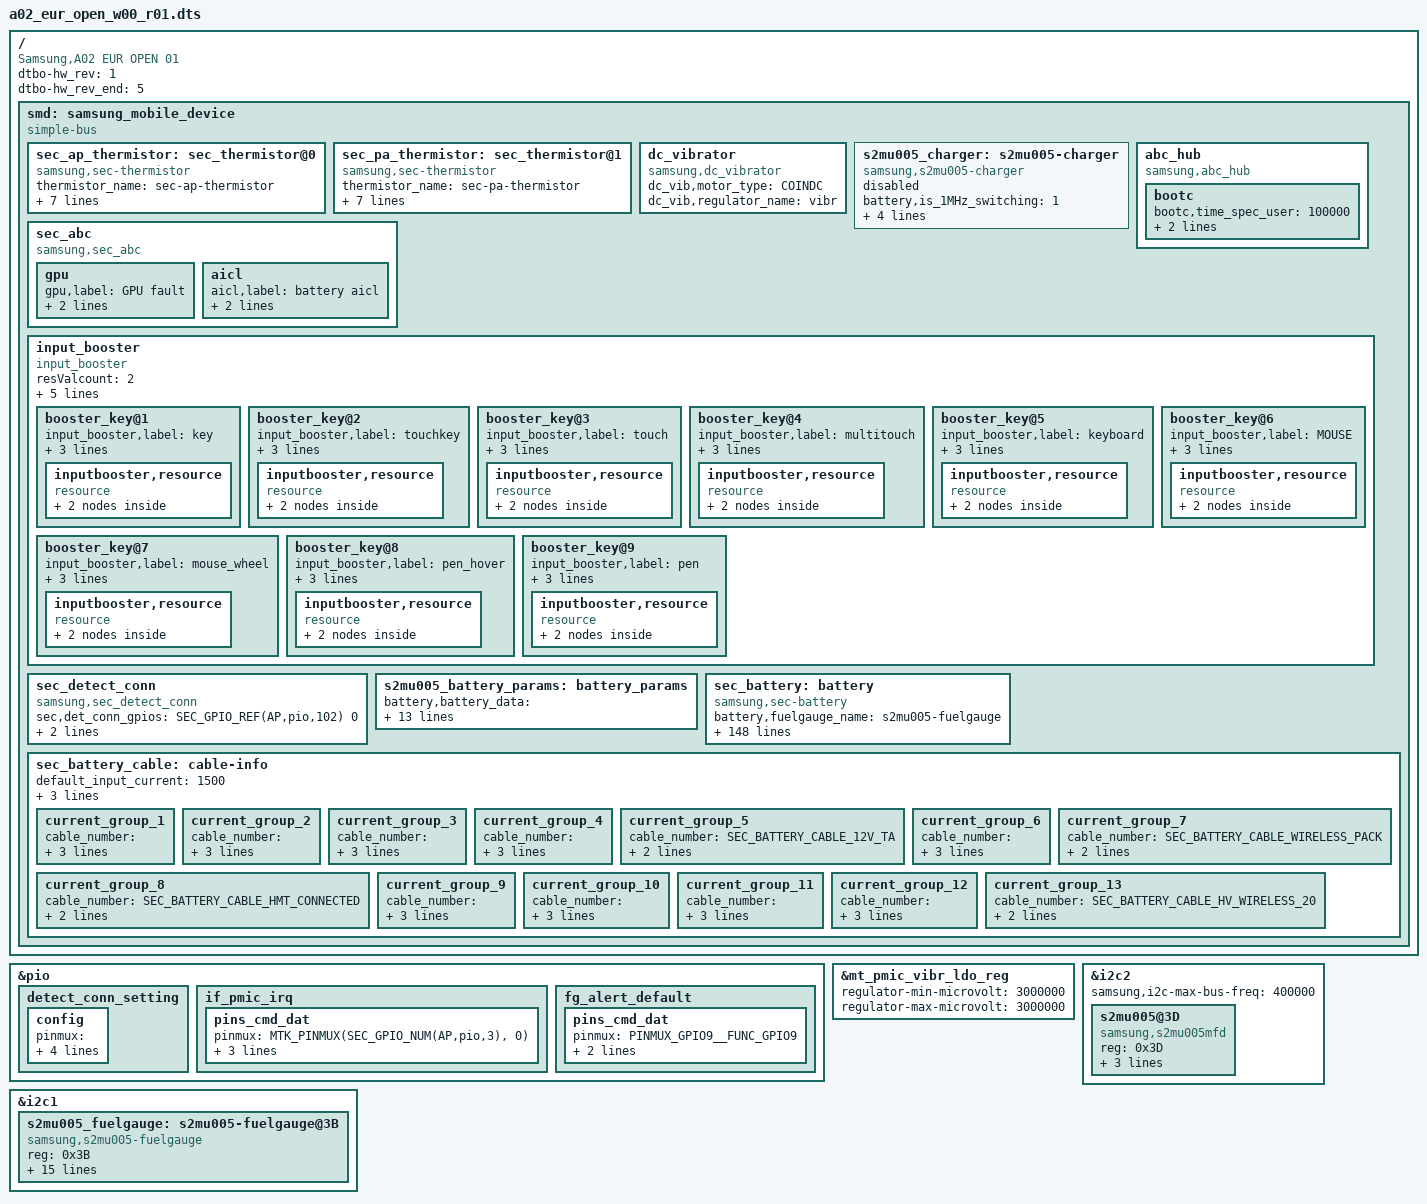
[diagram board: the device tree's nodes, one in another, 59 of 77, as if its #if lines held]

/*
 * Copyright (c) 2018 Samsung Electronics Co., Ltd.
 *              http://www.samsung.com
 *
 * This program is free software; you can redistribute it and/or modify
 * it under the terms of the GNU General Public License version 2 as
 * published by the Free Software Foundation.
*/

/dts-v1/;
/plugin/;
/ {
	fragment@smd {
		target-path = "/";
		__overlay__ {
			smd: samsung_mobile_device {
				compatible = "simple-bus";
			};
		};
	};
};

/* #include "../../../../../arm64/boot/dts/samsung/s2mu005_charger.dtsi" *//* From s2mu005_charger.py */

&smd {
	s2mu005_charger: s2mu005-charger {
		status = "disable";
		compatible = "samsung,s2mu005-charger";
		battery,is_1MHz_switching = <1>;
		battery,chg_gpio_en = <0>;
		battery,chg_polarity_en = <0>;
		battery,chg_gpio_status = <0>;
		battery,chg_polarity_status = <0>;
	};
};


/* #include "../../../../../arm64/boot/dts/samsung/sti_abc.dtsi" *//* From sti_abc.py */
#ifndef CONFIG_SEC_FACTORY

#if 0
&${gpio_sub_connect_conn_parent} {
	sub_detect_conn_setting: sub-detect-conn-setting {
		samsung,pins = SEC_GPIO(${gpio_sub_connect_conn});
		samsung,pin-function = <0xf>;
		samsung,pin-pud = <0>;
		samsung,pin-drv = <0>;
	};
};
#endif

#if 0
&${gpio_sub_connect_conn_parent2} {
	sub_detect_conn_setting2: sub-detect-conn-setting2 {
		samsung,pins = SEC_GPIO(${gpio_sub_connect_conn2});
		samsung,pin-function = <0xf>;
		samsung,pin-pud = <0>;
		samsung,pin-drv = <0>;
	};
};
#endif

#if 0
&${gpio_cam_connect_conn_parent} {
	cam_detect_conn_setting: cam-detect-conn-setting {
		samsung,pins = SEC_GPIO(${gpio_cam_connect_conn});
		samsung,pin-function = <0xf>;
		samsung,pin-pud = <0>;
		samsung,pin-drv = <0>;
	};
};
#endif

#if 0
&${det_gpio_num_parent} {
	detect_conn_setting: detect_conn_setting {
		config {
#if 0
			pins = SEC_GPIO(${det_gpio_num_0}),
			       SEC_GPIO(${det_gpio_num_1}),
			       SEC_GPIO(${det_gpio_num_2}),
			       SEC_GPIO(${det_gpio_num_3}),
			       SEC_GPIO(${det_gpio_num_4}),
#if 0
			       SEC_GPIO(${det_gpio_num_5}),
			       SEC_GPIO(${det_gpio_num_6}),
			       SEC_GPIO(${det_gpio_num_7});
#elif 0
			       SEC_GPIO(${det_gpio_num_5}),
			       SEC_GPIO(${det_gpio_num_6});
#else
			       SEC_GPIO(${det_gpio_num_5});
#endif
#elif 0
			pins = SEC_GPIO(${det_gpio_num_0}),
			       SEC_GPIO(${det_gpio_num_1}),
			       SEC_GPIO(${det_gpio_num_2}),
			       SEC_GPIO(${det_gpio_num_3}),
#if 0
			       SEC_GPIO(${det_gpio_num_4}),
			       SEC_GPIO(${det_gpio_num_6}),
			       SEC_GPIO(${det_gpio_num_7});
#elif 0
			       SEC_GPIO(${det_gpio_num_4}),
			       SEC_GPIO(${det_gpio_num_6});
#else
			       SEC_GPIO(${det_gpio_num_4});
#endif
#elif 0
			pins = SEC_GPIO(${det_gpio_num_0}),
			       SEC_GPIO(${det_gpio_num_1}),
			       SEC_GPIO(${det_gpio_num_2}),
#if 0
			       SEC_GPIO(${det_gpio_num_3}),
			       SEC_GPIO(${det_gpio_num_6}),
			       SEC_GPIO(${det_gpio_num_7});
#elif 0
			       SEC_GPIO(${det_gpio_num_3}),
			       SEC_GPIO(${det_gpio_num_6});
#else
			       SEC_GPIO(${det_gpio_num_3});
#endif
#elif 0
			pins = SEC_GPIO(${det_gpio_num_0}),
			       SEC_GPIO(${det_gpio_num_1}),
#if 0
			       SEC_GPIO(${det_gpio_num_2}),
			       SEC_GPIO(${det_gpio_num_6}),
			       SEC_GPIO(${det_gpio_num_7});
#elif 0
			       SEC_GPIO(${det_gpio_num_2}),
			       SEC_GPIO(${det_gpio_num_6});
#else
			       SEC_GPIO(${det_gpio_num_2});
#endif
#elif 0
			pins = SEC_GPIO(${det_gpio_num_0}),
#if 0
			       SEC_GPIO(${det_gpio_num_1}),
			       SEC_GPIO(${det_gpio_num_6}),
			       SEC_GPIO(${det_gpio_num_7});
#elif 0
			       SEC_GPIO(${det_gpio_num_1}),
			       SEC_GPIO(${det_gpio_num_6});
#else
			       SEC_GPIO(${det_gpio_num_1});
#endif
#elif 0
			pins =
#if 0
			       SEC_GPIO(${det_gpio_num_0}),
			       SEC_GPIO(${det_gpio_num_6}),
			       SEC_GPIO(${det_gpio_num_7});
#elif 0
			       SEC_GPIO(${det_gpio_num_0}),
			       SEC_GPIO(${det_gpio_num_6});
#else
			       SEC_GPIO(${det_gpio_num_0});
#endif
#elif 0
			pins = SEC_GPIO(${det_gpio_num_6}),
			       SEC_GPIO(${det_gpio_num_7});
#elif 0
			pins = SEC_GPIO(${det_gpio_num_6});
#endif
			drive-strength = <2>;
			bias-disable; /*NO PULL*/
			input-enable;
		};
	};
};
#endif /*use_dynamic_ap_gpio_detect*/

#if 0
&${det_pm_gpio_num_parent} {
	detect_conn_pm_setting: detect_conn_pm_setting {
#if 0 && 0
		pins = SEC_GPIO(${det_pm_gpio_num_0}),
		       SEC_GPIO(${det_pm_gpio_num_1});
#elif 0
		pins = SEC_GPIO(${det_pm_gpio_num_0});
#elif 0
		pins = SEC_GPIO(${det_pm_gpio_num_1});
#endif
		function = "normal";
		power-source = <0>;
		bias-disable; /*NO PULL*/
		input-enable;
	};
};
#endif /*use_dynamic_pm_gpio_detect*/

#endif /* not CONFIG_SEC_FACTORY */

&smd {
	sec_abc {
		compatible = "samsung,sec_abc";
		status = "okay";

		gpu {
			gpu,label="GPU fault";
#if 0
			gpu,threshold_count=<4>;
			gpu,threshold_time=<1200>;
#else
			gpu,threshold_count=<20>;
			gpu,threshold_time=<1200>;
#endif
		};
#if 0
		gpu_page {
			gpu_page,label="GPU page fault";
			gpu_page,threshold_count=<20>;
			gpu_page,threshold_time=<1200>;
		};
#endif
		aicl {
			aicl,label="battery aicl";
			aicl,threshold_count=<5>;
			aicl,threshold_time=<300>;
		};
#if 0
		motto {
			motto,label="motto info base";
			motto,info_bootcheck_base = <0x15860858>;
			motto,info_device_base = <0x1586085C>;
		};
#endif
	};
	abc_hub {
		compatible = "samsung,abc_hub";
		status = "okay";

#ifndef CONFIG_SEC_FACTORY
#if 0
#if 0 && 0
		pinctrl-names = "det_ap_connect","det_pm_connect";
		pinctrl-0 = <&detect_conn_setting>;
		pinctrl-1 = <&detect_conn_pm_setting>;
#elif 0
		pinctrl-names = "det_ap_connect";
		pinctrl-0 = <&detect_conn_setting>;
#elif 0
		pinctrl-names = "det_pm_connect";
		pinctrl-0 = <&detect_conn_pm_setting>;
#endif
/*not feature_abc_qcom_dt*/
#elif 0 && 0 && 0
		pinctrl-0 = <&sub_detect_conn_setting &sub_detect_conn_setting2 &cam_detect_conn_setting>;
#elif 0 && 0
		pinctrl-0 = <&sub_detect_conn_setting &cam_detect_conn_setting>;
#elif 0 && 0
		pinctrl-0 = <&sub_detect_conn_setting &sub_detect_conn_setting2>;
#elif 0
		pinctrl-0 = <&sub_detect_conn_setting>;
#elif 0
		pinctrl-0 = <&cam_detect_conn_setting>;
#endif
#endif /* not CONFIG_SEC_FACTORY */
		bootc {
			bootc,time_spec_user = <100000>; /* user binary user build */
			bootc,time_spec_eng = <150000>; /* user binary eng build */
			bootc,time_spec_fac = <100000>; /* factory binary */
		};

#ifndef CONFIG_SEC_FACTORY
#if 0
#if 0 || 0
		cond {
#if 0
			sec,det_conn_gpios = <
#if 0
					SEC_GPIO_REF(${det_gpio_num_0}) 0
#endif
#if 0
					SEC_GPIO_REF(${det_gpio_num_1}) 0
#endif
#if 0
					SEC_GPIO_REF(${det_gpio_num_2}) 0
#endif
#if 0
					SEC_GPIO_REF(${det_gpio_num_3}) 0
#endif
#if 0
					SEC_GPIO_REF(${det_gpio_num_4}) 0
#endif
#if 0
					SEC_GPIO_REF(${det_gpio_num_5}) 0
#endif
#if 0
					SEC_GPIO_REF(${det_gpio_num_6}) 0
#endif
#if 0
					SEC_GPIO_REF(${det_gpio_num_7}) 0
#endif
					>;
#if 0 || 0
			sec,det_conn_name =
#endif
#if 0 && 0
					"", "", "", "", "", "",
					"", "";
#elif 0
					"", "", "", "", "", "";
#elif 0
					"", "";
#endif
#endif /*use_dynamic_ap_gpio_detect*/

#if 0
			sec,det_pm_conn_gpios = <
#if 0
					SEC_GPIO_REF(${det_pm_gpio_num_0}) 0
#endif
#if 0
					SEC_GPIO_REF(${det_pm_gpio_num_1}) 0
#endif
					>;
#if 0 || 0
			sec,det_pm_conn_name =
#endif
#if 0 && 0
					"",
					"";
#elif 0
					"";
#elif 0
					"";
#endif
#endif /*use_dynamic_pm_gpio_detect */
		};
#endif /*use_dynamic_ap_gpio_detect || use_dynamic_pm_gpio_detect*/

/*not feature_abc_qcom_dt, feature_abc_lsi_dt*/
#elif 0 && 0 && 0
		cond {
			sec,det_conn_gpios = <SEC_GPIO_REF(${gpio_sub_connect_conn}) 0
						SEC_GPIO_REF(${gpio_sub_connect_conn2}) 0
						SEC_GPIO_REF(${gpio_cam_connect_conn}) 0>;
			sec,det_conn_name = "sub", "sub2", "cam";
			sec,det_conn_irq_type = <3>; /* BOTH EDGE */
		};
#elif 0 && 0
		cond {
			sec,det_conn_gpios = <SEC_GPIO_REF(${gpio_sub_connect_conn}) 0
						SEC_GPIO_REF(${gpio_cam_connect_conn}) 0>;
			sec,det_conn_name = "sub", "cam";
			sec,det_conn_irq_type = <3>; /* BOTH EDGE */
		};
#elif 0 && 0
		cond {
			sec,det_conn_gpios = <SEC_GPIO_REF(${gpio_sub_connect_conn}) 0
						SEC_GPIO_REF(${gpio_sub_connect_conn2}) 0>;
			sec,det_conn_name = "sub", "sub2";
			sec,det_conn_irq_type = <3>; /* BOTH EDGE */
		};
#elif 0
		cond {
			sec,det_conn_gpios = <SEC_GPIO_REF(${gpio_sub_connect_conn}) 0>;
			sec,det_conn_name = "sub";
			sec,det_conn_irq_type = <3>; /* BOTH EDGE */
		};
#elif 0
		cond {
			sec,det_conn_gpios = <SEC_GPIO_REF(${gpio_cam_connect_conn}) 0>;
			sec,det_conn_name = "cam";
			sec,det_conn_irq_type = <3>; /* BOTH EDGE */
		};
#endif
#endif /* not CONFIG_SEC_FACTORY */
	};
};

/* #include "../../../../../arm64/boot/dts/samsung/sec_pinctrl_wrapper.dtsi" *//* From sec_pinctrl_wrapper.py */
#define PIN_FUNC_INPUT		input-enable
#define PIN_FUNC_INPUT_WAKEUP	input-enable
#define PIN_FUNC_OUTPUT		output-enable
#define PIN_FUNC_OUTPUT_HIGH		output-high
#define PIN_FUNC_OUTPUT_LOW		output-low

#define PIN_PULL_NONE	bias-disable
#define PIN_PULL_DOWN	bias-pull-down
#define PIN_PULL_UP	bias-pull-up
#define PIN_PULL_OPEN	bias-high-impedance

/*
 * MTK_DRIVE_2mA  2
 * MTK_DRIVE_4mA  4
 * MTK_DRIVE_6mA  6
 * MTK_DRIVE_8mA  8
 * MTK_DRIVE_10mA 10
 * MTK_DRIVE_12mA 12
 * MTK_DRIVE_14mA 14
 * MTK_DRIVE_16mA 16
 */

#define PIN_DRV_LV1	2
#define PIN_DRV_LV2	4
#define PIN_DRV_LV3	6
#define PIN_DRV_LV4	8
#define PIN_DRV_LV5	10
#define PIN_DRV_LV6	12
#define PIN_DRV_LV7	14
#define PIN_DRV_LV8	16

#define PIN_EXPAND(pin) #pin

#define SEC_GPIO(src, type, num)	PIN_EXPAND(gpio##num)
#define SEC_GPIO_REF(src, type, num)	&type num
#define SEC_GPIO_NUM(src, type, num)	num
#define SEC_GPIO_TYPE(src, type, num)	&type

#define MTK_PINMUX(gpio, func) (MTK_PIN_NO(gpio) | func)

#define GPIO_CONFIG(_src, _type, _num, _func)		\
	pins_cmd_dat{					\
		pinmux = <MTK_PINMUX(SEC_GPIO_NUM(_src, _type, _num), 0)>;	\
		PIN_ ##_func;		\
	}

#define GPIO_CONFIG_PUD(_src, _type, _num, _func, _pull)	\
	pins_cmd_dat{					\
		pinmux = <MTK_PINMUX(SEC_GPIO_NUM(_src, _type, _num), 0)>;	\
		PIN_ ##_pull;				\
		PIN_ ##_func;		\
	}

#define GPIO_CONFIG_PUD_DRV(_src, _type, _num, _func, _pull, _drv)	\
	pins_cmd_dat{					\
		pinmux = <MTK_PINMUX(SEC_GPIO_NUM(_src, _type, _num), 0)>;	\
		PIN_ ##_pull;				\
		PIN_ ##_func;		\
		drive-strength = <PIN_ ##_drv>;	\
	}

#define SEC_ADC(type, num) <&type num>
#define SEC_ADC_OPT(type, num) ,<&type num>
#define SEC_ADC_NUM(type, num) <num>

/* #include "../../../../../arm64/boot/dts/samsung/input_booster.dtsi" *//* From input_booster.py */
/* Copyright (c) 2019, The Linux Foundation. All rights reserved.
 *
 * This program is free software; you can redistribute it and/or modify
 * it under the terms of the GNU General Public License version 2 and
 * only version 2 as published by the Free Software Foundation.
 *
 * This program is distributed in the hope that it will be useful,
 * but WITHOUT ANY WARRANTY; without even the implied warranty of
 * MERCHANTABILITY or FITNESS FOR A PARTICULAR PURPOSE.  See the
 * GNU General Public License for more details.
 */

&smd {
	input_booster {
		status = "okay";
		compatible = "input_booster";
		resValcount = "2";
		max_resource_count = "2";
		max_cluster_count = "3";
		#address-cells = <1>;
		#size-cells = <0>;

		/* Each Cpu Cluster Start Cpu */
		cpu_cluster_policy = "0";

		/* < CPU, DDR > */
		ib_release_values = "-1,-1";

		/* Select Allowed Resource Index Group */
		allowed_resources = "0,1";

		booster_key@1 {
			input_booster,label = "key";
			input_booster,type = <0>;	/* BOOSTER_DEVICE_KEY */

			/* Time table */
			input_booster,head_time = <200>;
			input_booster,tail_time = <0>;

			/* Resource Table Sequentially identified with index
			 * CPU's ID & Index : 0
			 * DDR's ID & Index : 1
			*/

			/* Input Booster Resource Frequency */
			inputbooster,resource {
				compatible = "resource";
				resource@1 {
					resource,label = "CPU";
					resource,value = <1274000 0>;
				};

				resource@2 {
					resource,label = "DDR";
					resource,value = <999 999>;
				};
			};
		};

		booster_key@2 {
			input_booster,label = "touchkey";
			input_booster,type = <1>;	/* BOOSTER_DEVICE_TOUCHKEY */

			/* Time table */
			input_booster,head_time = <1>;
			input_booster,tail_time = <300>;

			/* Input Booster Resource Frequency */
			inputbooster,resource {
				compatible = "resource";
				resource@1 {
					resource,label = "CPU";
					resource,value = <0 1053000>;
				};

				resource@2 {
					resource,label = "DDR";
					resource,value = <999 999>;
				};
			};
		};

		booster_key@3 {
			input_booster,label = "touch";
			input_booster,type = <2>;	/* BOOSTER_DEVICE_TOUCH */

			/* Time table */
			input_booster,head_time = <130>;
			input_booster,tail_time = <500>;

			/* Input Booster Resource Frequency */
			inputbooster,resource {
				compatible = "resource";
				resource@1 {
					resource,label = "CPU";
					resource,value = <1378000 1274000>;
				};

				resource@2 {
					resource,label = "DDR";
					resource,value = <999 999>;
				};
			};
		};

		booster_key@4 {
			input_booster,label = "multitouch";
			input_booster,type = <3>;	/* BOOSTER_DEVICE_MULTITOUCH */

			/* Time table */
			input_booster,head_time = <1000>;
			input_booster,tail_time = <500>;

			/* Input Booster Resource Frequency */
			inputbooster,resource {
				compatible = "resource";
				resource@1 {
					resource,label = "CPU";
					resource,value = <1378000 1274000>;
				};

				resource@2 {
					resource,label = "DDR";
					resource,value = <999 999>;
				};
			};
		};

		booster_key@5 {
			input_booster,label = "keyboard";
			input_booster,type = <4>;	/* BOOSTER_DEVICE_KEYBOARD */

			/* Time table */
			input_booster,head_time = <130>;
			input_booster,tail_time = <130>;

			/* Input Booster Resource Frequency */
			inputbooster,resource {
				compatible = "resource";
				resource@1 {
					resource,label = "CPU";
					resource,value = <1053000 1053000>;
				};

				resource@2 {
					resource,label = "DDR";
					resource,value = <999 999>;
				};
			};
		};

		booster_key@6 {
			input_booster,label = "MOUSE";
			input_booster,type = <5>;	/* BOOSTER_DEVICE_MOUSE */

			/* Time table */
			input_booster,head_time = <200>;
			input_booster,tail_time = <300>;

			/* Input Booster Resource Frequency */
			inputbooster,resource {
				compatible = "resource";
				resource@1 {
					resource,label = "CPU";
					resource,value = <1274000 1053000>;
				};

				resource@2 {
					resource,label = "DDR";
					resource,value = <999 999>;
				};
			};
		};

		booster_key@7 {
			input_booster,label = "mouse_wheel";
			input_booster,type = <6>;	/* BOOSTER_DEVICE_MOUSE */

			/* Time table */
			input_booster,head_time = <200>;
			input_booster,tail_time = <0>;

			/* Input Booster Resource Frequency */
			inputbooster,resource {
				compatible = "resource";
				resource@1 {
					resource,label = "CPU";
					resource,value = <1274000 0>;
				};

				resource@2 {
					resource,label = "DDR";
					resource,value = <999 999>;
				};
			};
		};

		booster_key@8 {
			input_booster,label = "pen_hover";
			input_booster,type = <7>;	/* BOOSTER_DEVICE_MOUSE */

			/* Time table */
			input_booster,head_time = <200>;
			input_booster,tail_time = <300>;

			/* Input Booster Resource Frequency */
			inputbooster,resource {
				compatible = "resource";
				resource@1 {
					resource,label = "CPU";
					resource,value = <1274000 1053000>;
				};

				resource@2 {
					resource,label = "DDR";
					resource,value = <999 999>;
				};
			};
		};

		booster_key@9 {
			input_booster,label = "pen";
			input_booster,type = <8>;	/* BOOSTER_DEVICE_MOUSE */

			/* Time table */
			input_booster,head_time = <200>;
			input_booster,tail_time = <600>;

			/* Input Booster Resource Frequency */
			inputbooster,resource {
				compatible = "resource";
				resource@1 {
					resource,label = "CPU";
					resource,value = <1274000 1053000>;
				};

				resource@2 {
					resource,label = "DDR";
					resource,value = <999 999>;
				};
			};
		};
		/* If you need to add new key type, add it this position */
	};
};

/* #include "../ap_mtk_mt6739.dtsi" */               /* From ap_mtk_mt6739.py */

#include <dt-bindings/clock/mt6739-clk.h>


/* /home/dpi/qb5_8814/workspace/P4_1716/android/kernel/kmodule/ap/mtk/mt6739/ap_mtk_mt6739.a02.01.dtsi */

#include "../../k39tv1_bsp_titan_hamster.dts"
#include "../../k39tv1_bsp_titan_hamster/gpio01.dtsi"



/* #include "../../../../../arm64/boot/dts/samsung/gpio_sec_detect_conn.dtsi" *//* From gpio_sec_detect_conn.py */
#ifdef CONFIG_SEC_FACTORY
#if 1
&pio {
	detect_conn_setting: detect_conn_setting {
		config {
#if 0
			pinmux = <MTK_PINMUX(SEC_GPIO_NUM(AP,pio,102), 0)>,
			       <MTK_PINMUX(SEC_GPIO_NUM(${det_gpio_num_1}), 0)>,
			       <MTK_PINMUX(SEC_GPIO_NUM(${det_gpio_num_2}), 0)>,
			       <MTK_PINMUX(SEC_GPIO_NUM(${det_gpio_num_3}), 0)>,
			       <MTK_PINMUX(SEC_GPIO_NUM(${det_gpio_num_4}), 0)>,
#if 0
			       <MTK_PINMUX(SEC_GPIO_NUM(${det_gpio_num_5}), 0)>,
			       <MTK_PINMUX(SEC_GPIO_NUM(${det_gpio_num_6}), 0)>,
			       <MTK_PINMUX(SEC_GPIO_NUM(${det_gpio_num_7}), 0)>;
#elif 0
			       <MTK_PINMUX(SEC_GPIO_NUM(${det_gpio_num_5}), 0)>,
			       <MTK_PINMUX(SEC_GPIO_NUM(${det_gpio_num_6}), 0)>;
#else
			       <MTK_PINMUX(SEC_GPIO_NUM(${det_gpio_num_5}), 0)>;
#endif
#elif 0
			pinmux = <MTK_PINMUX(SEC_GPIO_NUM(AP,pio,102), 0)>,
			       <MTK_PINMUX(SEC_GPIO_NUM(${det_gpio_num_1}), 0)>,
			       <MTK_PINMUX(SEC_GPIO_NUM(${det_gpio_num_2}), 0)>,
			       <MTK_PINMUX(SEC_GPIO_NUM(${det_gpio_num_3}), 0)>,
#if 0
			       <MTK_PINMUX(SEC_GPIO_NUM(${det_gpio_num_4}), 0)>,
			       <MTK_PINMUX(SEC_GPIO_NUM(${det_gpio_num_6}), 0)>,
			       <MTK_PINMUX(SEC_GPIO_NUM(${det_gpio_num_7}), 0)>;
#elif 0
			       <MTK_PINMUX(SEC_GPIO_NUM(${det_gpio_num_4}), 0)>,
			       <MTK_PINMUX(SEC_GPIO_NUM(${det_gpio_num_6}), 0)>;
#else
			       <MTK_PINMUX(SEC_GPIO_NUM(${det_gpio_num_4}), 0)>;
#endif
#elif 0
			pinmux = <MTK_PINMUX(SEC_GPIO_NUM(AP,pio,102), 0)>,
			       <MTK_PINMUX(SEC_GPIO_NUM(${det_gpio_num_1}), 0)>,
			       <MTK_PINMUX(SEC_GPIO_NUM(${det_gpio_num_2}), 0)>,
#if 0
			       <MTK_PINMUX(SEC_GPIO_NUM(${det_gpio_num_3}), 0)>,
			       <MTK_PINMUX(SEC_GPIO_NUM(${det_gpio_num_6}), 0)>,
			       <MTK_PINMUX(SEC_GPIO_NUM(${det_gpio_num_7}), 0)>;
#elif 0
			       <MTK_PINMUX(SEC_GPIO_NUM(${det_gpio_num_3}), 0)>,
			       <MTK_PINMUX(SEC_GPIO_NUM(${det_gpio_num_6}), 0)>;
#else
			       <MTK_PINMUX(SEC_GPIO_NUM(${det_gpio_num_3}), 0)>;
#endif
#elif 0
			pinmux = <MTK_PINMUX(SEC_GPIO_NUM(AP,pio,102), 0)>,
			       <MTK_PINMUX(SEC_GPIO_NUM(${det_gpio_num_1}), 0)>,
#if 0
			       <MTK_PINMUX(SEC_GPIO_NUM(${det_gpio_num_2}), 0)>,
			       <MTK_PINMUX(SEC_GPIO_NUM(${det_gpio_num_6}), 0)>,
			       <MTK_PINMUX(SEC_GPIO_NUM(${det_gpio_num_7}), 0)>;
#elif 0
			       <MTK_PINMUX(SEC_GPIO_NUM(${det_gpio_num_2}), 0)>,
			       <MTK_PINMUX(SEC_GPIO_NUM(${det_gpio_num_6}), 0)>;
#else
			       <MTK_PINMUX(SEC_GPIO_NUM(${det_gpio_num_2}), 0)>;
#endif
#elif 0
			pinmux = <MTK_PINMUX(SEC_GPIO_NUM(AP,pio,102), 0)>,
#if 0
			       <MTK_PINMUX(SEC_GPIO_NUM(${det_gpio_num_1}), 0)>,
			       <MTK_PINMUX(SEC_GPIO_NUM(${det_gpio_num_6}), 0)>,
			       <MTK_PINMUX(SEC_GPIO_NUM(${det_gpio_num_7}), 0)>;
#elif 0
			       <MTK_PINMUX(SEC_GPIO_NUM(${det_gpio_num_1}), 0)>,
			       <MTK_PINMUX(SEC_GPIO_NUM(${det_gpio_num_6}), 0)>;
#else
			       <MTK_PINMUX(SEC_GPIO_NUM(${det_gpio_num_1}), 0)>;
#endif
#elif 1
			pinmux =
#if 0
			       <MTK_PINMUX(SEC_GPIO_NUM(AP,pio,102), 0)>,
			       <MTK_PINMUX(SEC_GPIO_NUM(${det_gpio_num_6}), 0)>,
			       <MTK_PINMUX(SEC_GPIO_NUM(${det_gpio_num_7}), 0)>;
#elif 0
			       <MTK_PINMUX(SEC_GPIO_NUM(AP,pio,102), 0)>,
			       <MTK_PINMUX(SEC_GPIO_NUM(${det_gpio_num_6}), 0)>;
#else
			       <MTK_PINMUX(SEC_GPIO_NUM(AP,pio,102), 0)>;
#endif
#elif 0
			pinmux = <MTK_PINMUX(SEC_GPIO_NUM(${det_gpio_num_6}), 0)>,
			       <MTK_PINMUX(SEC_GPIO_NUM(${det_gpio_num_7}), 0)>;
#elif 0
			pinmux = <MTK_PINMUX(SEC_GPIO_NUM(${det_gpio_num_6}), 0)>;
#endif
			drive-strength = <2>;
			bias-disable; /*NO PULL*/
			input-enable;
		};
	};
};
#endif /*use_dynamic_ap_gpio_detect*/

#if 0
&${det_pm_gpio_num_parent} {
	detect_conn_pm_setting: detect_conn_pm_setting {
#if 0 && 0
		pinmux = <MTK_PINMUX(SEC_GPIO_NUM(${det_pm_gpio_num_0}), 0)>,
		       <MTK_PINMUX(SEC_GPIO_NUM(${det_pm_gpio_num_1}), 0)>;
#elif 0
		pinmux = <MTK_PINMUX(SEC_GPIO_NUM(${det_pm_gpio_num_0}), 0)>;
#elif 0
		pinmux = <MTK_PINMUX(SEC_GPIO_NUM(${det_pm_gpio_num_1}), 0)>;
#endif
		function = "normal";
		power-source = <0>;
		bias-disable; /*NO PULL*/
		input-enable;
	};
};
#endif /*use_dynamic_pm_gpio_detect*/

&smd {
	sec_detect_conn {
		compatible = "samsung,sec_detect_conn";
		status = "okay";

#if 1
		sec,det_conn_gpios = <
#if 1
					SEC_GPIO_REF(AP,pio,102) 0
#endif
#if 0
					SEC_GPIO_REF(${det_gpio_num_1}) 0
#endif
#if 0
					SEC_GPIO_REF(${det_gpio_num_2}) 0
#endif
#if 0
					SEC_GPIO_REF(${det_gpio_num_3}) 0
#endif
#if 0
					SEC_GPIO_REF(${det_gpio_num_4}) 0
#endif
#if 0
					SEC_GPIO_REF(${det_gpio_num_5}) 0
#endif
#if 0
					SEC_GPIO_REF(${det_gpio_num_6}) 0
#endif
#if 0
					SEC_GPIO_REF(${det_gpio_num_7}) 0
#endif
					>;
#if 1 || 0
		sec,det_conn_name =
#endif
#if 1 && 0
					"SUB_CONNECT", "", "", "", "", "",
					"", "";
#elif 1
					"SUB_CONNECT", "", "", "", "", "";
#elif 0
					"", "";
#endif
#endif /*use_dynamic_ap_gpio_detect*/

#if 0
		sec,det_pm_conn_gpios = <
#if 0
					SEC_GPIO_REF(${det_pm_gpio_num_0}) 0
#endif
#if 0
					SEC_GPIO_REF(${det_pm_gpio_num_1}) 0
#endif
					>;
#if 0 || 0
		sec,det_pm_conn_name =
#endif
#if 0 && 0
					"",
					"";
#elif 0
					"";
#elif 0
					"";
#endif
#endif /*use_dynamic_pm_gpio_detect*/

#if 1 && 0
		pinctrl-names = "det_ap_connect","det_pm_connect";
		pinctrl-0 = <&detect_conn_setting>;
		pinctrl-1 = <&detect_conn_pm_setting>;
#elif 1
		pinctrl-names = "det_ap_connect";
		pinctrl-0 = <&detect_conn_setting>;
#elif 0
		pinctrl-names = "det_pm_connect";
		pinctrl-0 = <&detect_conn_pm_setting>;
#endif
	};
};
#endif /* CONFIG_SEC_FACTORY */


/* #include "../../../../../arm64/boot/dts/samsung/pmic_MT6357.dtsi" *//* From pmic_MT6357.py */
#if 0 && 0
&mt_pmic_vfe28_ldo_reg {
    regulator-min-microvolt = <0>;
    regulator-max-microvolt = <0>;
     
     
};
#endif

#if 0 && 0
&mt_pmic_vxo22_ldo_reg {
    regulator-min-microvolt = <0>;
    regulator-max-microvolt = <0>;
     
     
};
#endif

#if 0 && 0
&mt_pmic_vrf18_ldo_reg {
    regulator-min-microvolt = <0>;
    regulator-max-microvolt = <0>;
     
     
};
#endif

#if 0 && 0
&mt_pmic_vrf12_ldo_reg {
    regulator-min-microvolt = <0>;
    regulator-max-microvolt = <0>;
     
     
};
#endif

#if 0 && 0
&mt_pmic_vefuse_ldo_reg {
    regulator-min-microvolt = <0>;
    regulator-max-microvolt = <0>;
     
     
};
#endif

#if 0 && 0
&mt_pmic_vcn33_wifi_ldo_reg {
    regulator-min-microvolt = <0>;
    regulator-max-microvolt = <0>;
     
     
};
#endif

#if 0 && 0
&mt_pmic_vcn28_ldo_reg {
    regulator-min-microvolt = <0>;
    regulator-max-microvolt = <0>;
     
     
};
#endif

#if 0 && 0
&mt_pmic_vcn18_ldo_reg {
    regulator-min-microvolt = <0>;
    regulator-max-microvolt = <0>;
     
     
};
#endif

#if 0 && 0
&mt_pmic_vcama_ldo_reg {
    regulator-min-microvolt = <0>;
    regulator-max-microvolt = <0>;
     
     
};
#endif

#if 0 && 0
&mt_pmic_vcamd_ldo_reg {
    regulator-min-microvolt = <0>;
    regulator-max-microvolt = <0>;
     
     
};
#endif

#if 0 && 0
&mt_pmic_vcamio_ldo_reg {
    regulator-min-microvolt = <0>;
    regulator-max-microvolt = <0>;
     
     
};
#endif

#if 0 && 0
&mt_pmic_vldo28_ldo_reg {
    regulator-min-microvolt = <0>;
    regulator-max-microvolt = <0>;
     
     
};
#endif

#if 0 && 0
&mt_pmic_vsram_others_ldo_reg {
    regulator-min-microvolt = <0>;
    regulator-max-microvolt = <0>;
     
     
};
#endif

#if 0 && 0
&mt_pmic_vsram_proc_ldo_reg {
    regulator-min-microvolt = <0>;
    regulator-max-microvolt = <0>;
     
     
};
#endif

#if 0 && 0
&mt_pmic_vaux18_ldo_reg {
    regulator-min-microvolt = <0>;
    regulator-max-microvolt = <0>;
     
     
};
#endif

#if 0 && 0
&mt_pmic_vaud28_ldo_reg {
    regulator-min-microvolt = <0>;
    regulator-max-microvolt = <0>;
     
     
};
#endif

#if 0 && 0
&mt_pmic_vio28_ldo_reg {
    regulator-min-microvolt = <0>;
    regulator-max-microvolt = <0>;
     
     
};
#endif

#if 0 && 0
&mt_pmic_vio18_ldo_reg {
    regulator-min-microvolt = <0>;
    regulator-max-microvolt = <0>;
     
     
};
#endif

#if 0 && 0
&mt_pmic_vdram_ldo_reg {
    regulator-min-microvolt = <0>;
    regulator-max-microvolt = <0>;
     
     
};
#endif

#if 0 && 0
&mt_pmic_vmc_ldo_reg {
    regulator-min-microvolt = <0>;
    regulator-max-microvolt = <0>;
     
     
};
#endif

#if 0 && 0
&mt_pmic_vmch_ldo_reg {
    regulator-min-microvolt = <0>;
    regulator-max-microvolt = <0>;
     
     
};
#endif

#if 0 && 0
&mt_pmic_vemc_ldo_reg {
    regulator-min-microvolt = <0>;
    regulator-max-microvolt = <0>;
     
     
};
#endif

#if 0 && 0
&mt_pmic_vsim1_ldo_reg {
    regulator-min-microvolt = <0>;
    regulator-max-microvolt = <0>;
     
     
};
#endif

#if 0 && 0
&mt_pmic_vsim2_ldo_reg {
    regulator-min-microvolt = <0>;
    regulator-max-microvolt = <0>;
     
     
};
#endif

#if 3000000 && 3000000
&mt_pmic_vibr_ldo_reg {
    regulator-min-microvolt = <3000000>;
    regulator-max-microvolt = <3000000>;
     
     
};
#endif

#if 0 && 0
&mt_pmic_vusb33_ldo_reg {
    regulator-min-microvolt = <0>;
    regulator-max-microvolt = <0>;
     
     
};
#endif

/* #include "../../../../../arm64/boot/dts/samsung/sec_thermistor.dtsi" *//* From sec_thermistor.py */
/ {
	fragment@smd {
		target-path = "/";
		__overlay__ {
			samsung_mobile_device {
				sec_ap_thermistor: sec_thermistor@0 {
					compatible = "samsung,sec-thermistor";
					status = "okay";
					thermistor_name = "sec-ap-thermistor";
					id = <0>;

					io-channels = SEC_ADC(auxadc,0);
					io-channel-names = "ap_therm";
					io-channel-ranges;
				};
			};
		};
	};
};

/* #include "../../../../../arm64/boot/dts/samsung/sec_thermistor-1.dtsi" *//* From sec_thermistor.py */
/ {
	fragment@smd {
		target-path = "/";
		__overlay__ {
			samsung_mobile_device {
				sec_pa_thermistor: sec_thermistor@1 {
					compatible = "samsung,sec-thermistor";
					status = "okay";
					thermistor_name = "sec-pa-thermistor";
					id = <1>;

					io-channels = SEC_ADC(auxadc,12);
					io-channel-names = "pa_therm";
					io-channel-ranges;
				};
			};
		};
	};
};

/* /home/dpi/qb5_8814/workspace/P4_1716/android/kernel/kmodule/hwmon/sec_thermistor/sec_thermistor_mtk.a02.dtsi */
/ {
	fragment@smd {
		target-path = "/";
		__overlay__ {
			samsung_mobile_device {
				sec_thermistor@0 {
					adc_array = <112 133 157 184 219 264 319 377 457 563
								682 821 967 1175 1389 1578 1743 2126
								2405 2708 3123 3402>;

					temp_array = <850 800 750 700 650 600 550 500 450 400
								350 300 250 200 150 100 50 0
								(-50) (-100) (-150) (-200)>;
				};
			};
		};
	};
};

/ {
	fragment@smd {
		target-path = "/";
		__overlay__ {
			samsung_mobile_device {
				sec_thermistor@1 {
					adc_array = <123 145 173 200 238 286 346 406 496 610
								729 880 1052 1249 1470 1664 1844 2220
								2516 2859 3226 3499>;

					temp_array = <850 800 750 700 650 600 550 500 450 400
								350 300 250 200 150 100 50 0
								(-50) (-100) (-150) (-200)>;
				};
			};
		};
	};
};

/* #include "../s2mu005.dtsi" */                     /* From s2mu005.py */
&pio {
	if_pmic_irq: if_pmic_irq {
		pins_cmd_dat {
			pinmux = <MTK_PINMUX(SEC_GPIO_NUM(AP,pio,3), 0)>;
			slew-rate = <1>;
			bias-disable;
			input-enable;
		};
	};
};

&i2c2 {
	#address-cells = <1>;
	#size-cells = <0>;
	status = "okay";
	samsung,i2c-max-bus-freq = <400000>;
	s2mu005@3D {
		status = "okay";
		compatible = "samsung,s2mu005mfd";
		reg = <0x3D>;
		pinctrl-names = "default";
		pinctrl-0 = <&if_pmic_irq>;
		s2mu005,irq-gpio = <SEC_GPIO_REF(AP,pio,3) 1>;
		s2mu005,wakeup;
	};
};

/* #include "../../../../../arm64/boot/dts/samsung/s2mu005_fuelgauge.dtsi" *//* From s2mu005_fuelgauge.py */

&i2c1 {
	status = "okay";

	s2mu005_fuelgauge: s2mu005-fuelgauge@3B {
		compatible = "samsung,s2mu005-fuelgauge";
		reg = <0x3B>;
		pinctrl-names = "default";
		pinctrl-0 = <&fg_alert_default>;
		fuelgauge,fuel_int = <SEC_GPIO_REF(AP,pio,9) 0>;
		fuelgauge,fuel_alert_soc = <1>;
		fuelgauge,fuel_alert_vol = <3300>;
		fuelgauge,low_temp_limit = <100>;
		fuelgauge,low_voltage_limit_lowtemp = <3100>;
		fuelgauge,i_socr_coeff = <84>;
		fuelgauge,sw_vbat_l_recovery_vol = <3465>;
		fuelgauge,capacity_max = <1000>;
		fuelgauge,capacity_max_margin = <200>;
		fuelgauge,capacity_min = <0>;
		fuelgauge,capacity_calculation_type = <28>;
		fuelgauge,capacity_full = <3000>;
		fuelgauge,type_str = "SDI";
		fuelgauge,fg_log_enable = <1>;
	};
};

&smd {
	s2mu005_battery_params: battery_params {
		battery,battery_data =
		<
			/***** battery data for 4.35 *****/
			/* battery,battery_table3 */
			6 11 132 10 1 10 138 9 23 9
			171 8 70 8 233 7 155 7 61 7
			223 6 169 6 128 6 96 6 70 6
			42 6 1 6 211 5 146 5 123 5
			223 3 7 2 107 8 0 8 149 7
			43 7 192 6 85 6 235 5 128 5
			21 5 171 4 64 4 213 3 107 3
			0 3 149 2 43 2 192 1 85 1
			235 0 128 0 21 0 241 15

			/* battery,battery_table4 */
			10 10 10 10 48 47 48 47 47 47
			47 48 49 50 51 54 57 64 77 106
			158 221

			/* battery,batcap */
			0x2B 0x14 0x8 0x13 /* [0x0F] [0x0E] [0x11] [0x10] */

			/* battery,accum */
			0x00 0x08 /* [0x44] [0x45] */

			/* battery,soc_arr_val */
			10521 10000 9479 8958 8438 7917 7396 6875 6354 5833
			5312 4791 4271 3750 3229 2708 2187 1667 1146 625
			104 (-75)

			/* battery,ocv_arr_val */
			43778 43142 42507 41922 41362 40834 40339 39890 39508 39047
			38588 38327 38126 37968 37843 37707 37507 37281 36962 36850
			34840 32536

			/* battery,tuning */
			0x00 /* [0x13] */

			/***** battery data for 4.33 *****/
			/* battery,battery_table3 */
			6 11 132 10 1 10 138 9 23 9
			171 8 70 8 233 7 155 7 61 7
			223 6 169 6 128 6 96 6 70 6
			42 6 1 6 211 5 146 5 123 5
			223 3 7 2 132 8 24 8 172 7
			65 7 213 6 105 6 253 5 145 5
			37 5 185 4 77 4 225 3 117 3
			9 3 157 2 49 2 197 1 89 1
			237 0 130 0 22 0 240 15

			/* battery,battery_table4 */
			10 10 10 10 48 47 48 47 47 47
			47 48 49 50 51 54 57 64 77 106
			158 221

			/* battery,batcap */
			0x2B 0x48 0x8 0x1D /* [0x0F] [0x0E] [0x11] [0x10] */

			/* battery,accum */
			0x00 0x8 /* [0x44] [0x45] */

			/* battery,soc_arr_val */
			10646 10119 9592 9065 8538 8011 7484 6957 6430 5903
			5376 4849 4321 3794 3267 2740 2213 1686 1159 632
			105 (-76)

			/* battery,ocv_arr_val */
			43778 43142 42507 41922 41362 40834 40339 39890 39508 39047
			38588 38327 38126 37968 37843 37707 37507 37281 36962 36850
			34840 32536

			/* battery,tuning */
			0x00 /* [0x13] */

			/***** battery data for 4.31 *****/
			/* battery,battery_table3 */
			6 11 132 10 1 10 138 9 23 9
			171 8 70 8 233 7 155 7 61 7
			223 6 169 6 128 6 96 6 70 6
			42 6 1 6 211 5 146 5 123 5
			223 3 7 2 203 8 92 8 236 7
			125 7 13 7 158 6 46 6 191 5
			79 5 224 4 113 4 1 4 146 3
			34 3 179 2 67 2 212 1 101 1
			245 0 134 0 22 0 240 15

			/* battery,battery_table4 */
			10 10 10 10 48 47 48 47 47 47
			47 48 49 50 51 54 57 64 77 106
			158 221

			/* battery,batcap */
			0x29 0xEC 0x7 0xDC /* [0x0F] [0x0E] [0x11] [0x10] */

			/* battery,accum */
			0x00 0x8 /* [0x44] [0x45] */

			/* battery,soc_arr_val */
			10992 10448 9903 9359 8815 8271 7727 7182 6638 6094
			5550 5006 4462 3918 3373 2829 2285 1741 1197 653
			109 (-79)

			/* battery,ocv_arr_val */
			43778 43142 42507 41922 41362 40834 40339 39890 39508 39047
			38588 38327 38126 37968 37843 37707 37507 37281 36962 36850
			34840 32536

			/* battery,tuning */
			0x00 /* [0x13] */

			/***** battery data for 4.29 *****/
			/* battery,battery_table3 */
			6 11 132 10 1 10 138 9 23 9
			171 8 70 8 233 7 155 7 61 7
			223 6 169 6 128 6 96 6 70 6
			42 6 1 6 211 5 146 5 123 5
			223 3 7 2 166 8 56 8 203 7
			93 7 240 6 130 6 20 6 167 5
			57 5 203 4 94 4 240 3 131 3
			21 3 167 2 58 2 204 1 95 1
			241 0 132 0 22 0 240 15

			/* battery,battery_table4 */
			10 10 10 10 48 47 48 47 47 47
			47 48 49 50 51 54 57 64 77 106
			158 221

			/* battery,batcap */
			0x2A 0xA0 0x7 0xFE /* [0x0F] [0x0E] [0x11] [0x10] */

			/* battery,accum */
			0x00 0x8 /* [0x44] [0x45] */

			/* battery,soc_arr_val */
			10810 10275 9740 9205 8670 8135 7599 7064 6529 5993
			5458 4923 4388 3853 3318 2783 2248 1712 1177 642
			107 (-77)

			/* battery,ocv_arr_val */
			43778 43142 42507 41922 41362 40834 40339 39890 39508 39047
			38588 38327 38126 37968 37843 37707 37507 37281 36962 36850
			34840 32536

			/* battery,tuning */
			0x00 /* [0x13] */

			/***** battery data for 4.24 *****/
			/* battery,battery_table3 */
			6 11 132 10 1 10 138 9 23 9
			171 8 70 8 233 7 155 7 61 7
			223 6 169 6 128 6 96 6 70 6
			42 6 1 6 211 5 146 5 123 5
			223 3 7 2 53 9 192 8 75 8
			215 7 98 7 237 6 121 6 4 6
			143 5 27 5 166 4 49 4 189 3
			72 3 211 2 95 2 234 1 117 1
			1 1 140 0 23 0 239 15

			/* battery,battery_table4 */
			10 10 10 10 48 47 48 47 47 47
			47 48 49 50 51 54 57 64 77 106
			158 221

			/* battery,batcap */
			0x28 0xC 0x7 0x82 /* [0x0F] [0x0E] [0x11] [0x10] */

			/* battery,accum */
			0x00 0x8 /* [0x44] [0x45] */

			/* battery,soc_arr_val */
			11507 10937 10367 9798 9228 8659 8089 7519 6949 6380
			5810 5240 4671 4101 3532 2962 2392 1823 1253 684
			114 (-82)

			/* battery,ocv_arr_val */
			43778 43142 42507 41922 41362 40834 40339 39890 39508 39047
			38588 38327 38126 37968 37843 37707 37507 37281 36962 36850
			34840 32536

			/* battery,tuning */
			0x00 /* [0x13] */
			>;

		battery,battery_table3 = <
			6 11 132 10 1 10 138 9 23 9
			171 8 70 8 233 7 155 7 61 7
			223 6 169 6 128 6 96 6 70 6
			42 6 1 6 211 5 146 5 123 5
			223 3 7 2 107 8 0 8 149 7
			43 7 192 6 85 6 235 5 128 5
			21 5 171 4 64 4 213 3 107 3
			0 3 149 2 43 2 192 1 85 1
			235 0 128 0 21 0 241 15
			>;

		battery,battery_table4 = <
			10 10 10 10 48 47 48 47 47 47
			47 48 49 50 51 54 57 64 77 106
			158 221
			>;

		battery,batcap = <0x2B 0x14 0x8 0x13>; /* [0x0F] [0x0E] [0x11] [0x10] */

		battery,soc_arr_evt2 = <
			10521 10000 9479 8958 8438 7917 7396 6875 6354 5833
			5312 4791 4271 3750 3229 2708 2187 1667 1146 625
			104 (-75)
			>;
		battery,ocv_arr_evt2 = <
			43778 43142 42507 41922 41362 40834 40339 39890 39508 39047
			38588 38327 38126 37968 37843 37707 37507 37281 36962 36850
			34840 32536
			>;
		battery,FG_Accumulative_rate_evt2 = <0x00 0x08>; /* 0x44 0x45 */
		battery,tuning = <0x00>; /* [0x13] */
		battery,data_ver = <0x04>;
	};
};

&smd {
	battery {
		battery,fuelgauge_name = "s2mu005-fuelgauge";
		battery,fgsrc_switch_name = "s2mu005-fuelgauge"; /* Fuelgauge voltage source */
	};
};

/* /home/dpi/qb5_8814/workspace/P4_1716/android/kernel/kmodule/battery/fuelgauge/s2mu005_fuelgauge/s2mu005_fuelgauge.a02.dtsi */

&pio {
	fg_alert_default: fg_alert_default {
		pins_cmd_dat {
			pinmux = <PINMUX_GPIO9__FUNC_GPIO9>;
			slew-rate = <0>;
			bias-disable;
		};
	};
};

&s2mu005_fuelgauge {
	fuelgauge,capacity_full = <5000>;
};

&s2mu005_battery_params {
	battery,battery_data =
	<
		/***** battery data for 4.35 *****/
		/* battery,battery_table3 */
		248 10 117 10 242 9 128 9 19 9
		171 8 73 8 208 7 156 7 70 7
		230 6 172 6 130 6 97 6 71 6
		45 6 7 6 223 5 155 5 130 5
		152 4 156 1 106 8 0 8 150 7
		44 7 194 6 88 6 238 5 132 5
		26 5 177 4 71 4 221 3 115 3
		9 3 159 2 53 2 203 1 97 1
		247 0 141 0 35 0 227 15

		/* battery,battery_table4 */
		10 10 10 10 51 51 51 52 51 51
		51 51 52 52 52 53 54 55 57 60
		65 154

		/* battery,batcap */
		0x49 0xC4 0x0E 0xC0 /* [0x0F] [0x0E] [0x11] [0x10] */

		/* battery,accum */
		0x00 0x08 /* [0x44] [0x45] */

		/* battery,soc_arr_val */
		10517 10000 9483 8966 8448 7931 7414 6897 6379 5862
		5345 4828 4310 3793 3276 2759 2241 1724 1207 690
		172 (-141)

		/* battery,ocv_arr_val */
		43711 43071 42430 41873 41344 40837 40355 39768 39513 39091
		38625 38338 38133 37972 37846 37721 37533 37336 37007 36884
		35744 32014

		/* battery,tuning */
		0x00 /* [0x13] */

		/***** battery data for 4.33 *****/
		/* battery,battery_table3 */
		233 10 108 10 239 9 123 9 11 9
		162 8 62 8 229 7 150 7 35 7
		216 6 166 6 126 6 94 6 68 6
		36 6 250 5 201 5 139 5 120 5
		98 3 90 1 118 8 11 8 159 7
		51 7 199 6 92 6 240 5 132 5
		24 5 173 4 65 4 213 3 105 3
		254 2 146 2 38 2 186 1 79 1
		227 0 119 0 11 0 136 15

		/* battery,battery_table4 */
		10 10 10 10 54 54 54 54 54 54
		54 54 55 55 56 56 56 57 59 63
		76 101

		/* battery,batcap */
		0x4B 0x5C 0x0F 0x12 /* [0x0F] [0x0E] [0x11] [0x10] */

		/* battery,accum */
		0x00 0x8 /* [0x44] [0x45] */

		/* battery,soc_arr_val */
		10578 10052 9525 8999 8473 7947 7421 6895 6369 5842
		5316 4790 4264 3738 3212 2686 2160 1633 1107 581
		55 (-584)

		/* battery,ocv_arr_val */
		43638 43028 42419 41849 41305 40789 40302 39869 39480 38923
		38557 38311 38115 37959 37830 37674 37472 37233 36929 36837
		34229 31691

		/* battery,tuning */
		0x00 /* [0x13] */

		/***** battery data for 4.31 *****/
		/* battery,battery_table3 */
		233 10 108 10 239 9 123 9 11 9
		162 8 62 8 229 7 150 7 35 7
		216 6 166 6 126 6 94 6 68 6
		36 6 250 5 201 5 139 5 120 5
		98 3 90 1 159 8 49 8 195 7
		85 7 232 6 122 6 12 6 158 5
		49 5 195 4 85 4 231 3 122 3
		12 3 158 2 48 2 195 1 85 1
		231 0 121 0 12 0 136 15

		/* battery,battery_table4 */
		10 10 10 10 54 54 54 54 54 54
		54 54 55 55 56 56 56 57 59 63
		76 101

		/* battery,batcap */
		0x49 0xF8 0x0E 0xCB /* [0x0F] [0x0E] [0x11] [0x10] */

		/* battery,accum */
		0x00 0x8 /* [0x44] [0x45] */

		/* battery,soc_arr_val */
		10774 10238 9702 9166 8630 8094 7559 7023 6487 5951
		5415 4879 4343 3807 3271 2736 2200 1664 1128 592
		56 (-586)

		/* battery,ocv_arr_val */
		43638 43028 42419 41849 41305 40789 40302 39869 39480 38923
		38557 38311 38115 37959 37830 37674 37472 37233 36929 36837
		34229 31691

		/* battery,tuning */
		0x00 /* [0x13] */

		/***** battery data for 4.29 *****/
		/* battery,battery_table3 */
		233 10 108 10 239 9 123 9 11 9
		162 8 62 8 229 7 150 7 35 7
		216 6 166 6 126 6 94 6 68 6
		36 6 250 5 201 5 139 5 120 5
		98 3 90 1 203 8 91 8 235 7
		123 7 11 7 155 6 43 6 187 5
		75 5 219 4 107 4 251 3 139 3
		27 3 171 2 60 2 204 1 92 1
		236 0 124 0 12 0 136 15

		/* battery,battery_table4 */
		10 10 10 10 54 54 54 54 54 54
		54 54 55 55 56 56 56 57 59 63
		76 101

		/* battery,batcap */
		0x48 0x84 0x0E 0x80 /* [0x0F] [0x0E] [0x11] [0x10] */

		/* battery,accum */
		0x00 0x8 /* [0x44] [0x45] */

		/* battery,soc_arr_val */
		10990 10443 9897 9350 8803 8257 7710 7163 6617 6070
		5524 4977 4430 3884 3337 2790 2244 1697 1150 604
		57 (-588)

		/* battery,ocv_arr_val */
		43638 43028 42419 41849 41305 40789 40302 39869 39480 38923
		38557 38311 38115 37959 37830 37674 37472 37233 36929 36837
		34229 31691

		/* battery,tuning */
		0x00 /* [0x13] */

		/***** battery data for 4.24 *****/
		/* battery,battery_table3 */
		233 10 108 10 239 9 123 9 11 9
		162 8 62 8 229 7 150 7 35 7
		216 6 166 6 126 6 94 6 68 6
		36 6 250 5 201 5 139 5 120 5
		98 3 90 1 54 9 192 8 75 8
		214 7 97 7 235 6 118 6 1 6
		139 5 22 5 161 4 44 4 182 3
		65 3 204 2 87 2 225 1 108 1
		247 0 130 0 12 0 136 15

		/* battery,battery_table4 */
		10 10 10 10 54 54 54 54 54 54
		54 54 55 55 56 56 56 57 59 63
		76 101

		/* battery,batcap */
		0x45 0x3C 0x0D 0xD8 /* [0x0F] [0x0E] [0x11] [0x10] */

		/* battery,accum */
		0x00 0x8 /* [0x44] [0x45] */

		/* battery,soc_arr_val */
		11511 10939 10366 9793 9221 8648 8076 7503 6931 6358
		5786 5213 4640 4068 3495 2923 2350 1778 1205 632
		60 (-592)

		/* battery,ocv_arr_val */
		43638 43028 42419 41849 41305 40789 40302 39869 39480 38923
		38557 38311 38115 37959 37830 37674 37472 37233 36929 36837
		34229 31691

		/* battery,tuning */
		0x00 /* [0x13] */
		>;

	battery,battery_table3 = <
		248 10 117 10 242 9 128 9 19 9
		171 8 73 8 208 7 156 7 70 7
		230 6 172 6 130 6 97 6 71 6
		45 6 7 6 223 5 155 5 130 5
		152 4 156 1 106 8 0 8 150 7
		44 7 194 6 88 6 238 5 132 5
		26 5 177 4 71 4 221 3 115 3
		9 3 159 2 53 2 203 1 97 1
		247 0 141 0 35 0 227 15
		>;

	battery,battery_table4 = <
		10 10 10 10 51 51 51 52 51 51
		51 51 52 52 52 53 54 55 57 60
		65 154
		>;

	battery,batcap = <0x49 0xC4 0x0E 0xC0>; /* [0x0F] [0x0E] [0x11] [0x10] */

	battery,soc_arr_evt2 = <
		10517 10000 9483 8966 8448 7931 7414 6897 6379 5862
		5345 4828 4310 3793 3276 2759 2241 1724 1207 690
		172 (-141)
		>;
	battery,ocv_arr_evt2 = <
		43711 43071 42430 41873 41344 40837 40355 39768 39513 39091
		38625 38338 38133 37972 37846 37721 37533 37336 37007 36884
		35744 32014
		>;
	battery,FG_Accumulative_rate_evt2 = <0x00 0x08>; /* 0x44 0x45 */
	battery,tuning = <0x00>; /* [0x13] */
	battery,data_ver = <0x02>;
};


/* #include "../../../../../arm64/boot/dts/samsung/battery_common.dtsi" *//* From battery_common.py */
#include <dt-bindings/battery/sec-battery.h>

&smd {
	sec_battery: battery {
		status = "okay";
		compatible = "samsung,sec-battery";
		battery,vendor = "Battery";
		battery,charger_name = "s2mu005-charger";
		battery,technology = <2>; /* POWER_SUPPLY_TECHNOLOGY_LION */

		battery,batt_data_version = <1>;

		battery,temp_adc_type = <SEC_BATTERY_ADC_TYPE_AP>; /* SEC_BATTERY_ADC_TYPE_AP */
		battery,adc_check_count = <5>;
		battery,temp_check_type = <SEC_BATTERY_TEMP_CHECK_NONE>;
		battery,usb_temp_check_type = <SEC_BATTERY_TEMP_CHECK_NONE>;
		battery,chg_temp_check_type = <SEC_BATTERY_TEMP_CHECK_NONE>;
		battery,wpc_temp_check_type = <SEC_BATTERY_TEMP_CHECK_NONE>;

		battery,thermal_source = <SEC_BATTERY_THERMAL_SOURCE_NONE>; /* SEC_BATTERY_THERMAL_SOURCE_NONE */
		battery,usb_thermal_source = <SEC_BATTERY_THERMAL_SOURCE_NONE>; /* SEC_BATTERY_THERMAL_SOURCE_NONE */
		battery,chg_thermal_source = <SEC_BATTERY_THERMAL_SOURCE_NONE>; /* SEC_BATTERY_THERMAL_SOURCE_NONE */
		battery,wpc_thermal_source = <SEC_BATTERY_THERMAL_SOURCE_NONE>; /* SEC_BATTERY_THERMAL_SOURCE_NONE */

		battery,polling_time = <10 30 30 30 3600>;

		battery,cable_check_type = <4>; /* SEC_BATTERY_CABLE_CHECK_PSY */
		battery,cable_source_type = <SEC_BATTERY_CABLE_SOURCE_EXTERNAL>;
		battery,polling_type = <SEC_BATTERY_MONITOR_ALARM>; /* SEC_BATTERY_MONITOR_ALARM */
		battery,monitor_initial_count = <0>;

		battery,battery_check_type = <0>; /* SEC_BATTERY_CHECK_NONE */

		battery,ovp_uvlo_check_type = <SEC_BATTERY_OVP_UVLO_CHGPOLLING>; /* SEC_BATTERY_OVP_UVLO_CHGPOLLING */

		battery,temp_check_count = <1>;
		battery,temp_highlimit_threshold_event = <800>;
		battery,temp_highlimit_recovery_event = <780>;
		battery,temp_high_threshold_event = <500>;
		battery,temp_high_recovery_event = <480>;
		battery,temp_low_threshold_event = <0>;
		battery,temp_low_recovery_event = <20>;
		battery,temp_highlimit_threshold_normal = <800>;
		battery,temp_highlimit_recovery_normal = <780>;
		battery,temp_high_threshold_normal = <500>;
		battery,temp_high_recovery_normal = <480>;
		battery,temp_low_threshold_normal = <0>;
		battery,temp_low_recovery_normal = <20>;
		battery,temp_highlimit_threshold_lpm = <800>;
		battery,temp_highlimit_recovery_lpm = <780>;
		battery,temp_high_threshold_lpm = <500>;
		battery,temp_high_recovery_lpm = <480>;
		battery,temp_low_threshold_lpm = <0>;
		battery,temp_low_recovery_lpm = <20>;
		battery,wpc_high_threshold_normal = <450>;
		battery,wpc_high_recovery_normal = <430>;
		battery,wpc_low_threshold_normal = <0>;
		battery,wpc_low_recovery_normal = <20>;
		battery,full_check_type = <SEC_BATTERY_FULLCHARGED_CHGPSY>;
		battery,full_check_type_2nd = <SEC_BATTERY_FULLCHARGED_CHGPSY>;
		battery,full_check_count = <1>;
		battery,chg_gpio_full_check = <0>;
		battery,chg_polarity_full_check = <1>;

		battery,chg_high_temp = <460>;
		battery,chg_high_temp_recovery = <440>;
		battery,chg_input_limit_current = <1000>;
		battery,chg_charging_limit_current = <1400>;

		battery,wpc_temp_control_source = <TEMP_CONTROL_SOURCE_BAT_THM>;
		battery,wpc_high_temp = <380>;
		battery,wpc_high_temp_recovery = <360>;
		battery,wpc_input_limit_current = <600>;
		battery,wpc_charging_limit_current = <1000>;
		battery,wpc_temp_lcd_on_control_source = <TEMP_CONTROL_SOURCE_BAT_THM>;
		battery,wpc_lcd_on_high_temp = <380>;
		battery,wpc_lcd_on_high_temp_rec = <360>;
		battery,wpc_lcd_on_input_limit_current = <450>;

		battery,wpc_store_high_temp = <360>;
		battery,wpc_store_high_temp_recovery = <340>;
		battery,wpc_store_charging_limit_current = <400>;
		battery,wpc_store_lcd_on_high_temp = <360>;
		battery,wpc_store_lcd_on_high_temp_rec = <300>;
		battery,wpc_store_lcd_on_charging_limit_current = <400>;

		battery,sleep_mode_limit_current = <500>;
		battery,wc_full_input_limit_current = <100>;

		battery,mix_high_temp = <420>;
		battery,mix_high_chg_temp = <500>;
		battery,mix_high_temp_recovery = <390>;

		battery,full_condition_type = <(SEC_BATTERY_FULL_CONDITION_NOTIMEFULL | SEC_BATTERY_FULL_CONDITION_VCELL)>;
		battery,full_condition_soc = <93>;
		battery,full_condition_vcell = <4250>;

		battery,recharge_check_count = <1>;
		battery,recharge_condition_type = <SEC_BATTERY_RECHARGE_CONDITION_VCELL>;
		battery,recharge_condition_soc = <98>;
		battery,recharge_condition_vcell = <4280>;

		battery,charging_total_time = <14400>;
		battery,hv_charging_total_time = <10800>;
		battery,normal_charging_total_time = <18000>;
		battery,usb_charging_total_time = <36000>;
		battery,recharging_total_time = <5400>;
		battery,charging_reset_time = <0>;

		battery,chg_float_voltage = <4350>;

		battery,pre_afc_work_delay = <2000>;
		battery,pre_wc_afc_work_delay = <4000>;
		battery,pre_afc_input_current = <500>;
		battery,pre_wc_afc_input_current = <500>;
		battery,prepare_ta_delay = <0>; /* msec */

		battery,swelling_high_temp_block = <410>;
		battery,swelling_high_temp_recov = <390>;
		battery,swelling_low_temp_block_1st = <150>;
		battery,swelling_low_temp_recov_1st = <170>;
		battery,swelling_low_temp_block_2nd = <50>;
		battery,swelling_low_temp_recov_2nd = <70>;

		battery,swelling_drop_float_voltage = <4150>;
		battery,swelling_high_rechg_voltage = <4000>;
		battery,swelling_low_rechg_voltage = <4000>;

		battery,siop_input_limit_current = <1200>;
		battery,siop_charging_limit_current = <1000>;
		battery,siop_hv_input_limit_current = <700>;
		battery,siop_hv_input_limit_current_2nd = <550>;
		battery,siop_hv_charging_limit_current = <1000>;

		battery,rp_current_rp1 = <500>;
		battery,rp_current_rp2 = <1500>;
		battery,rp_current_rp3 = <3000>;
		battery,rp_current_rdu_rp3 = <2100>;
		battery,rp_current_abnormal_rp3 = <1800>;

		battery,pd_charging_charge_power = <15000>;
		battery,max_charging_current = <2350>;

		battery,store_mode_charging_max = <70>;
		battery,store_mode_charging_min = <60>;

		battery,wireless_cc_cv = <85>;
		battery,wireless_otg_input_current = <900>;

		/* cycle, chg_float_voltage, recharge_condition_vcell, full_condition_vcell, full_condition_soc, step charging condition */
		battery,age_data = <0 4350 4280 4250 93
			300 4330 4260 4230 92
			400 4310 4240 4210 91
			700 4290 4220 4190 90
			1000 4240 4170 4140 89>;

		battery,max_input_voltage = <9000>; /* mV */
		battery,max_input_current = <3000>;  /* mA */

		battery,cisd_alg_index = <8>;
		battery,cisd_max_voltage_thr = <4400>; /* batttery ovp dettection voltage */
		battery,ignore_cisd_index = <0 960>; /* Do not use AFC_FAIL to DROP_VALUE */
		battery,ignore_cisd_index_d = <0 120>; /* Do not use AFC_FAIL_PER_DAY to DROP_VALUE_PER_DAY */

		battery,expired_time = <10800>;
		battery,recharging_expired_time = <5400>;

		battery,battery_full_capacity = <3300>;

		io-channels = <&auxadc 1>;
		io-channel-names = "adc-temp", "n/a", "n/a", "n/a", "n/a";
	};

	/* sec_battery_cable
	 *   0	UNKNOWN,
	 *   1	NONE,
	 *   2	PREPARE_TA,
	 *   3	TA,
	 *   4	USB,
	 *   5	USB_CDP,
	 *   6	9V_TA,
	 *   7	9V_ERR,
	 *   8	9V_UNKNOWN,
	 *   9	12V_TA,
	 *  10	WIRELESS,
	 *  11	HV_WIRELESS,
	 *  12	PMA_WIRELESS,
	 *  13	WIRELESS_PACK,
	 *  14	CABLE_WIRELESS_HV_PACK,
	 *  15	WIRELESS_STAND,
	 *  16	WIRELESS_HV_STAND,
	 *  17	QC20,
	 *  18	QC30,
	 *  19	PDIC,
	 *  20	UARTOFF,
	 *  21	OTG,
	 *  22	LAN_HUB,
	 *  23	POWER_SHARING,
	 *  24	HMT_CONNECTED,
	 *  25	HMT_CHARGE,
	 *  26	HV_TA_CHG_LIMIT,
	 *  27	WIRELESS_VEHICLE,
	 *  28	WIRELESS_HV_VEHICLE,
	 *  29	PREPARE_WIRELESS_HV,
	 *  30  TIMEOUT,
	 *  31  SMART_OTG,
	 *  32  SMART_NOTG,
	 *  33  WIRELESS_TX,
	 *  34	HV_WIRELESS_20,
	 *  35	HV_WIRELESS_20_LIMIT,
	 *  36	WIRELESS_FAKE,
	 *  37  PREPARE_WIRELESS_20,
	 *  38	CABLE_PDIC_APDO,
	 *  39	CABLE_MAX,
	 */
	sec_battery_cable: cable-info {
		default_input_current = <1800>;
		default_charging_current = <2100>;
		full_check_current_1st = <350>;
		full_check_current_2nd = <200>;

		current_group_1 {
			cable_number = <
				SEC_BATTERY_CABLE_PREPARE_TA
				SEC_BATTERY_CABLE_PDIC
				SEC_BATTERY_CABLE_OTG
				SEC_BATTERY_CABLE_LAN_HUB
				SEC_BATTERY_CABLE_POWER_SHARING>;
			input_current = <500>;
			charging_current = <500>;
		};
		current_group_2 {
			cable_number = <
				SEC_BATTERY_CABLE_HMT_CHARGE
				SEC_BATTERY_CABLE_SMART_OTG>;
			input_current = <1000>;
			charging_current = <1000>;
		};
		current_group_3 {
			cable_number = <
				SEC_BATTERY_CABLE_USB_CDP
				SEC_BATTERY_CABLE_SMART_NOTG>;
			input_current = <1500>;
			charging_current = <1500>;
		};
		current_group_4 {
			cable_number = <SEC_BATTERY_CABLE_9V_TA SEC_BATTERY_CABLE_9V_ERR
				SEC_BATTERY_CABLE_9V_UNKNOWN SEC_BATTERY_CABLE_QC20
				SEC_BATTERY_CABLE_QC30 SEC_BATTERY_CABLE_9V_POGO>;
			input_current = <1650>;
			charging_current = <2350>;
		};
		current_group_5 {
			cable_number = <SEC_BATTERY_CABLE_12V_TA>;
			input_current = <1650>;
			charging_current = <2350>;
		};
		current_group_6 {
			cable_number = <
				SEC_BATTERY_CABLE_WIRELESS
				SEC_BATTERY_CABLE_PMA_WIRELESS
				SEC_BATTERY_CABLE_WIRELESS_STAND
				SEC_BATTERY_CABLE_WIRELESS_VEHICLE
				SEC_BATTERY_CABLE_WIRELESS_TX
				SEC_BATTERY_CABLE_WIRELESS_FAKE>;
			input_current = <800>;
			charging_current = <2350>;
		};
		current_group_7 {
			cable_number = <SEC_BATTERY_CABLE_WIRELESS_PACK>;
			input_current = <700>;
			charging_current = <2350>;
		};
		current_group_8 {
			cable_number = <SEC_BATTERY_CABLE_HMT_CONNECTED>;
			input_current = <1000>;
			charging_current = <450>;
		};
		current_group_9 {
			cable_number = <SEC_BATTERY_CABLE_HV_TA_CHG_LIMIT>;
			input_current = <1800>;
			charging_current = <1800>;
		};
		current_group_10 {
			cable_number = <
				SEC_BATTERY_CABLE_HV_WIRELESS
				SEC_BATTERY_CABLE_WIRELESS_HV_PACK
				SEC_BATTERY_CABLE_WIRELESS_HV_STAND
				SEC_BATTERY_CABLE_WIRELESS_HV_VEHICLE
				SEC_BATTERY_CABLE_HV_WIRELESS_20_LIMIT>;
			input_current = <650>;
			charging_current = <2350>;
		};
		current_group_11 {
			cable_number = <
				SEC_BATTERY_CABLE_PREPARE_WIRELESS_HV
				SEC_BATTERY_CABLE_PREPARE_WIRELESS_20>;
			input_current = <500>;
			charging_current = <1200>;
		};
		current_group_12 {
			cable_number = <
				SEC_BATTERY_CABLE_NONE
				SEC_BATTERY_CABLE_USB
				SEC_BATTERY_CABLE_TIMEOUT>;
			input_current = <475>;
			charging_current = <550>;
		};
		current_group_13 {
			cable_number = <SEC_BATTERY_CABLE_HV_WIRELESS_20>;
			input_current = <1200>;
			charging_current = <2350>;
		};
	};
};

/* /home/dpi/qb5_8814/workspace/P4_1716/android/kernel/kmodule/battery/common/dts/battery_common.a02.dtsi */
&sec_battery {
	pinctrl-names = "default";

	battery,chip_vendor = "MTK";

	battery,temp_adc_type = <SEC_BATTERY_ADC_TYPE_AP_LEGACY>;
	battery,temp_check_type = <SEC_BATTERY_TEMP_CHECK_TEMP>;
	battery,chg_temp_check_type = <SEC_BATTERY_TEMP_CHECK_NONE>;

	battery,thermal_source = <SEC_BATTERY_THERMAL_SOURCE_ADC>;
	battery,chg_thermal_source = <SEC_BATTERY_THERMAL_SOURCE_FG>;

	battery,temp_table_adc = <
				117 130 185 219 260 314 379 456 551 614
				663 826 915 991 1185 1413 1682 1974 2150 2306
				2520 2607 2937 3250 3563
				>;
	battery,temp_table_data = <
				850 800 700 650 600 550 500 450 400 370
				350 300 270 250 200 150 100 50 30 0
				(-30) (-50) (-100) (-150) (-200)
				>;

	battery,overheatlimit_threshold = <700>;
	battery,overheatlimit_recovery = <680>;
	battery,usb_protection_temp = <610>;
	battery,temp_gap_bat_usb = <200>;

	battery,wire_warm_overheat_thresh = <500>;
	battery,wire_normal_warm_thresh = <420>;
	battery,wire_cool1_normal_thresh = <150>;
	battery,wire_cool2_cool1_thresh = <150>;
	battery,wire_cool3_cool2_thresh = <50>;
	battery,wire_cold_cool3_thresh = <0>;

	battery,wire_warm_current = <1300>;	/* 0.27C */
	battery,wire_cool1_current = <1800>;	/* 0.72C */
	battery,wire_cool2_current = <850>;	/* 0.18C */
	battery,wire_cool3_current = <450>;	/* 0.1C */

	battery,high_temp_topoff = <250>;
	battery,low_temp_topoff = <250>;
	battery,high_temp_float = <4150>;
	battery,low_temp_float = <4350>;

	battery,full_check_type = <SEC_BATTERY_FULLCHARGED_FG_CURRENT>;
	battery,full_check_type_2nd = <SEC_BATTERY_FULLCHARGED_FG_CURRENT>;

	battery,full_condition_vcell = <4250>;

	battery,recharge_condition_vcell = <4280>;

	battery,chg_float_voltage = <4350>;

	battery,swelling_high_rechg_voltage = <4000>;
	battery,swelling_low_rechg_voltage = <4200>;

	battery,max_charging_current = <1800>;
	battery,max_charging_charge_power = <7500>; /* 7.5W */

	/* cycle, chg_float_voltage, recharge_condition_vcell, full_condition_vcell, full_condition_soc */
	battery,age_data = <0 4350 4280 4250 93
		300 4330 4260 4230 92
		400 4310 4240 4210 91
		700 4290 4220 4190 90
		1000 4240 4170 4140 89>;

	battery,health_condition = <
		/* CYCLE ASOC */
		900 0  /* GOOD */
		1200 0 /* NORMAL */
		1500 0 /* AGED */
		>;

	battery,standard_curr = <1800>;
	battery,expired_time = <19200>; /* 230min + 90min margin */
	battery,battery_full_capacity = <5000>;
	battery,cisd_max_voltage_thr = <5000>; /* batttery ovp dettection voltage */
	battery,ttf_capacity = <4900>;
	battery,cv_data = <
		1411	853	2278
		1263	862	2188
		1298	871	2098
		1212	882	1978
		1146	891	1879
		1077	900	1768
		979	910	1635
		951	920	1483
		885	930	1330
		808	940	1146
		747	950	973
		680	960	739
		612	970	485
		549	980	235
		515	990	51
		490	1000	0
	>;
};

&sec_battery_cable {
	default_input_current = <1500>;
	default_charging_current = <1800>;
	full_check_current_1st = <500>;
	full_check_current_2nd = <250>;

	current_group_4 {
		input_current = <1500>;
		charging_current = <1800>;
	};
	current_group_5 {
		input_current = <1500>;
		charging_current = <1800>;
	};
	current_group_6 {
		charging_current = <1800>;
	};
	current_group_7 {
		charging_current = <1800>;
	};
	current_group_9 {
		charging_current = <1800>;
	};
	current_group_10 {
		charging_current = <1800>;
	};
	current_group_13 {
		charging_current = <1800>;
	};
};

/* #include "../../../../../arm64/boot/dts/samsung/dc_vibrator.dtsi" *//* From dc_vibrator.py */
/ {
	fragment@smd {
		target-path = "/";
			__overlay__ {
				samsung_mobile_device {
					dc_vibrator {
						compatible = "samsung,dc_vibrator";
						status = "okay";
						dc_vib,motor_type = "COINDC";
						dc_vib,regulator_name = "vibr";
					};
				};
			};
	};
};

/* revision devicetree for general */
#include "mt6739.a02_eur_open.01.dtsi"

/ {
	compatible = "Samsung,A02 EUR OPEN 01","Mediatek,MT6739";
	dtbo-hw_rev = <1>;
	dtbo-hw_rev_end = <5>;
};
